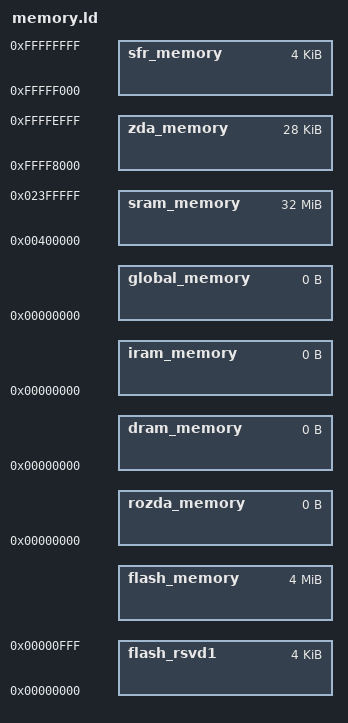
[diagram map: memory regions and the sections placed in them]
MEMORY {
    sram_memory           : ORIGIN = 0x00400000, LENGTH = 32M
    zda_memory            : ORIGIN = 0xffff8000, LENGTH = 28K
    sfr_memory		  : ORIGIN = 0xfffff000, LENGTH = 4K

    flash_rsvd1           : ORIGIN = 0x00000000, LENGTH = 0x1000
    flash_memory          : ORIGIN = .,          LENGTH = 4M - 0x1000

    // These memory region(s) needed for the default linkmap
    rozda_memory: ORIGIN = 0, LENGTH = 0
    dram_memory : ORIGIN = 0, LENGTH = 0
    iram_memory : ORIGIN = 0, LENGTH = 0
    global_memory: ORIGIN = 0, LENGTH = 0
}
